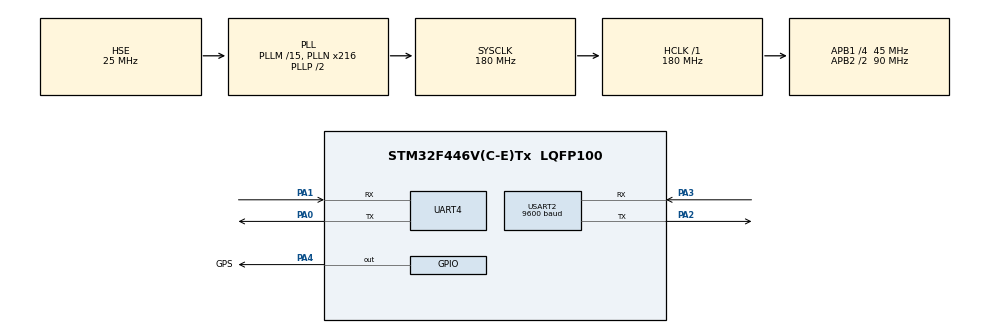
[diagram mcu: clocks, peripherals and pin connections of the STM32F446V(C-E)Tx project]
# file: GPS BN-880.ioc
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Mcu.Family=STM32F4
Mcu.Name=STM32F446V(C-E)Tx
Mcu.Package=LQFP100
NVIC.PriorityGroup=NVIC_PRIORITYGROUP_4
NVIC.USART2_IRQn=true\:0\:0\:false\:false\:true\:true\:true
PA0-WKUP.Mode=Asynchronous
PA0-WKUP.Signal=UART4_TX
PA1.Mode=Asynchronous
PA1.Signal=UART4_RX
PA2.Mode=Asynchronous
PA2.Signal=USART2_TX
PA3.Mode=Asynchronous
PA3.Signal=USART2_RX
PA4.GPIO_Label=GPS
PA4.Signal=GPIO_Output
PH0-OSC_IN.Mode=HSE-External-Oscillator
PH0-OSC_IN.Signal=RCC_OSC_IN
PH1-OSC_OUT.Mode=HSE-External-Oscillator
PH1-OSC_OUT.Signal=RCC_OSC_OUT
ProjectManager.HeapSize=0x200
ProjectManager.StackSize=0x400
ProjectManager.TargetToolchain=MDK-ARM V5.27
RCC.AHBFreq_Value=180000000
RCC.APB1CLKDivider=RCC_HCLK_DIV4
RCC.APB1Freq_Value=45000000
RCC.APB1TimFreq_Value=90000000
RCC.APB2CLKDivider=RCC_HCLK_DIV2
RCC.APB2Freq_Value=90000000
RCC.APB2TimFreq_Value=180000000
RCC.CortexFreq_Value=180000000
RCC.HCLKFreq_Value=180000000
RCC.PLLM=15
RCC.PLLN=216
RCC.PLLSourceVirtual=RCC_PLLSOURCE_HSE
RCC.SYSCLKFreq_VALUE=180000000
RCC.SYSCLKSource=RCC_SYSCLKSOURCE_PLLCLK
RCC.USBFreq_Value=180000000
RCC.VCOOutputFreq_Value=360000000
UART4.VirtualMode=Asynchronous
USART2.BaudRate=9600
USART2.VirtualMode=VM_ASYNC
board=custom

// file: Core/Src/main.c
/* USER CODE BEGIN Header */
/**
  ******************************************************************************
  * @file           : main.c
  * @brief          : Main program body
  ******************************************************************************
  * @attention
  *
  * <h2><center>&copy; Copyright (c) 2021 STMicroelectronics.
  * All rights reserved.</center></h2>
  *
  * This software component is licensed by ST under BSD 3-Clause license,
  * the "License"; You may not use this file except in compliance with the
  * License. You may obtain a copy of the License at:
  *                        opensource.org/licenses/BSD-3-Clause
  *
  ******************************************************************************
  */
/* USER CODE END Header */
#include "main.h"
#include "usart.h"
#include "gpio.h"

/* USER CODE BEGIN Includes */

#include "gps.h"
/* USER CODE END Includes */

/* USER CODE BEGIN PV */

	uint8_t BootingHeader[] ={"Booting\r\n"};
	uint8_t BootHeader[] ={"Booted\r\n"};
	uint8_t gpsNotReadyHeader[] ={"GPS Not Ready\r\n"};
/* USER CODE END PV */

void SystemClock_Config(void);

/* USER CODE BEGIN 0 */
void HAL_UART_RxCpltCallback(UART_HandleTypeDef *huart)
{
  GPS_CallBack();
}
/* USER CODE END 0 */

int main(void)
{

  /* MCU Configuration--------------------------------------------------------*/

  /* Reset of all peripherals, Initializes the Flash interface and the Systick. */
  HAL_Init();

  /* Configure the system clock */
  SystemClock_Config();

  /* Initialize all configured peripherals */
  MX_GPIO_Init();
  MX_USART2_UART_Init();
  MX_UART4_Init();
  /* USER CODE BEGIN 2 */
	HAL_UART_Transmit(&huart4,BootingHeader,sizeof(BootingHeader),1000);
  HAL_GPIO_WritePin(GPS_GPIO_Port, GPS_Pin, GPIO_PIN_SET);
  GPS_Init();
	HAL_UART_Transmit(&huart4,BootHeader,sizeof(BootHeader),1000);
  /* USER CODE END 2 */
	uint8_t gpsSuccess=0;
	GPS_t tempGPS;
  /* Infinite loop */
  while (1)
  {
		gpsSuccess=GPS_Process();
		if(gpsSuccess==0)
		{
			Print_GPS_Data(&huart4,&tempGPS);
		}
		else
		{
			//HAL_UART_Transmit(&huart4,gpsNotReadyHeader,sizeof(gpsNotReadyHeader),1000);
			//HAL_Delay(1000);
		}
  }
}

void SystemClock_Config(void)
{
  RCC_OscInitTypeDef RCC_OscInitStruct = {0};
  RCC_ClkInitTypeDef RCC_ClkInitStruct = {0};

  /** Configure the main internal regulator output voltage
  */
  __HAL_RCC_PWR_CLK_ENABLE();
  __HAL_PWR_VOLTAGESCALING_CONFIG(PWR_REGULATOR_VOLTAGE_SCALE1);
  /** Initializes the RCC Oscillators according to the specified parameters
  * in the RCC_OscInitTypeDef structure.
  */
  RCC_OscInitStruct.OscillatorType = RCC_OSCILLATORTYPE_HSE;
  RCC_OscInitStruct.HSEState = RCC_HSE_ON;
  RCC_OscInitStruct.PLL.PLLState = RCC_PLL_ON;
  RCC_OscInitStruct.PLL.PLLSource = RCC_PLLSOURCE_HSE;
  RCC_OscInitStruct.PLL.PLLM = 15;
  RCC_OscInitStruct.PLL.PLLN = 216;
  RCC_OscInitStruct.PLL.PLLP = RCC_PLLP_DIV2;
  RCC_OscInitStruct.PLL.PLLQ = 2;
  RCC_OscInitStruct.PLL.PLLR = 2;
  if (HAL_RCC_OscConfig(&RCC_OscInitStruct) != HAL_OK)
  {
    Error_Handler();
  }
  /** Activate the Over-Drive mode
  */
  if (HAL_PWREx_EnableOverDrive() != HAL_OK)
  {
    Error_Handler();
  }
  /** Initializes the CPU, AHB and APB buses clocks
  */
  RCC_ClkInitStruct.ClockType = RCC_CLOCKTYPE_HCLK|RCC_CLOCKTYPE_SYSCLK
                              |RCC_CLOCKTYPE_PCLK1|RCC_CLOCKTYPE_PCLK2;
  RCC_ClkInitStruct.SYSCLKSource = RCC_SYSCLKSOURCE_PLLCLK;
  RCC_ClkInitStruct.AHBCLKDivider = RCC_SYSCLK_DIV1;
  RCC_ClkInitStruct.APB1CLKDivider = RCC_HCLK_DIV4;
  RCC_ClkInitStruct.APB2CLKDivider = RCC_HCLK_DIV2;

  if (HAL_RCC_ClockConfig(&RCC_ClkInitStruct, FLASH_LATENCY_5) != HAL_OK)
  {
    Error_Handler();
  }
}

void Error_Handler(void)
{
  __disable_irq();
  while (1)
  {
  }
}

/************************ (C) COPYRIGHT STMicroelectronics *****END OF FILE****/
